# YTM32B1ME0 register map
Vendor: YTMicro; File version: 1.6
YTM32B1ME0 YTMicro Microcontroller
CPU: CM33 r0p4, little endian, MPU, FPU, 2 interrupt priority bits
Registers are 32-bit, read-write, reset 0x0 unless marked. A register's access mark holds for its fields unless they carry their own. Offsets are from the block's base; lines under a group give offsets from that group; [hi:lo] are bit positions; {n}, {i} and the like mark numbered series; 'fields as' and 'values as' point back to an identical list; <NAME> marks a mode.

## Memory map
0x40008000 DMA0 size 0x1200
0x40010000 EFM size 0x400 — Embedded FLASH Module
0x40011000 GPIOA size 0xFF
0x40011100 GPIOB size 0xFF
0x40011200 GPIOC size 0xFF
0x40011300 GPIOD size 0xFF
0x40011400 GPIOE size 0xFF
0x40012000 PCTRLA size 0x80 — PORT Control
0x40013000 PCTRLB size 0x80 — PORT Control
0x40014000 PCTRLC size 0x80 — PORT Control
0x40015000 PCTRLD size 0x80 — PORT Control
0x40016000 PCTRLE size 0x80 — PORT Control
0x4001B000 LINFlexD0 size 0xA0
0x4001C000 LINFlexD1 size 0xA0
0x4001D000 LINFlexD2 size 0xA0
0x4001E000 LINFlexD3 size 0xA0
0x4001F000 LINFlexD4 size 0xA0
0x40020000 LINFlexD5 size 0xA0
0x40023000 I2C0 size 0x120
0x40024000 I2C1 size 0x120
0x40025000 I2C2 size 0x120
0x4002A000 SPI0 size 0x28
0x4002B000 SPI1 size 0x28
0x4002C000 SPI2 size 0x28
0x4002D000 SPI3 size 0x28
0x4002E000 SPI4 size 0x28
0x4002F000 SPI5 size 0x28
0x40030000 CAN0 size 0xC08 — FlexCAN module
0x40034000 CAN1 size 0xC08 — FlexCAN module
0x40038000 CAN2 size 0xC08 — FlexCAN module
0x4003C000 CAN3 size 0xC08 — FlexCAN module
0x4003D000 CAN4 size 0xC08 — FlexCAN module
0x4003E000 CAN5 size 0xC08 — FlexCAN module
0x40040000 ADC0 size 0x54
0x40041000 ADC1 size 0x54
0x40043000 ACMP0 size 0x24 — Analog comparator module
0x40046000 PTU0 size 0x198 — Programmable Trigger Unit
0x40047000 PTU1 size 0x198 — Programmable Trigger Unit
0x40048000 TMU size 0x80 — Trigger Multiplexer Module
0x40049000 eTMR0 size 0x268 — Enhanced timer
0x4004A000 eTMR1 size 0x268 — Enhanced timer
0x4004B000 eTMR2 size 0x268 — Enhanced timer
0x4004C000 eTMR3 size 0x268 — Enhanced timer
0x4004D000 eTMR4 size 0x268 — Enhanced timer
0x4004E000 eTMR5 size 0x268 — Enhanced timer
0x40054000 TMR0 size 0x4C
0x4005A000 pTMR0 size 0x140 — Periodic timer
0x4005D000 lpTMR0 size 0x18 — Low Power Timer
0x40060000 RTC size 0x20
0x40061000 REGFILE size 0x20
0x40062000 WKU size 0x2C — Wake-up Unit
0x40065000 CRC0 size 0x10 — Cyclic Redundancy Check
0x40066000 TRNG size 0x60
0x40067000 HCU size 0xB8 — Hardware Cryptography Unit
0x4006A000 WDG0 size 0x1C — Watchdog module
0x4006B000 EWDG0 size 0x14 — External Watchdog
0x40071000 INTM size 0x12C — Interrupt Monitor
0x40072000 EMU0 size 0x12C — ECC Management Unit
0x4007B000 CIM size 0x58 — Chip Integration Module
0x4007C000 SCU size 0x6C — System Clock Unit of Microcontroller
0x4007D000 IPC size 0x1FC — IP Control
0x4007E000 PCU size 0x20 — Power control unit
0x4007F000 RCU size 0x8 — Reset Contru Unit of Microcontroller

## REGFILE
Base 0x40061000; register names take the prefix REGFILE_
{0x0+4i} DR{i} (i=0..7)
  [31:0] DATA — The data value stored at register file block. The register is only reseted by POR.

## GPIOA
Base 0x40011000; register names take the prefix GPIOA_
0x00 PDOR
  [31:0] PDO — When configured for general-purpose output, it shows the logic level on the corresponding pin.
0x04 PSOR wo
  [31:0] PSO — Writing to this register will update the contents of the corresponding bit in PDOR. 0b - No change. 1b - Corresponding bit in PDOR is set to logic 1.
0x08 PCOR wo
  [31:0] PCO — Writing to this register will update the contents of the corresponding bit in PDOR. 0b - No change. 1b - Corresponding bit in PDOR is set to logic 0.
0x0C PTOR wo
  [31:0] PTO — Writing to this register will update the contents of the corresponding bit in PDOR. 0b - No change. 1b - Corresponding bit in PDOR is set to the inverse of its existing logic state.
0x10 PDIR ro
  [31:0] PDI — When configured for digital function, it shows the logic level on the corresponding pin. ewline When configured for analog function, it always reads 0.
0x14 POER
  [31:0] POE — Configure the corresponding pin for output. 0b - Port output disable 1b - Port output enable
0x18 PIER reset 0xFFFFFFFF
  [31:0] PIE — Configure the corresponding pin for input. 0b - Port input disable 1b - Port input enable
0x1C PIFR
  [31:0] PIF — Indicate the detection for the defined event in PCR[IRQC] of the corresponding pin. 0b - No event detected. 1b - The event defined in PCR[IRQC] is detected.
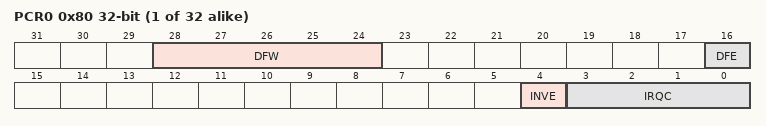
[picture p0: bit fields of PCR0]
{0x80+4i} PCR{i} (i=0..31)
  [28:24] DFW — The digital filter configuration is valid in all digital pin muxing modes. Glitches that are longer than this register setting will pass through the digital filter, and glitches that are equal to or less than this register setting are filtered. Changing the filter length must be done only after all filters are disabled.
  [16] DFE
  [4] INVE — Invert the input logic level when configured for digital function.
  [3:0] IRQC
    0=Disabled; 1=DMA request on rising edge; 2=DMA request on falling edge; 3=DMA request on either edge; 8=Interrupt when logic 0; 9=Interrupt on rising-edge; 10=Interrupt on falling-edge; 11=Interrupt on either edge; 12=Interrupt when logic 1

## GPIOB
Base 0x40011100; register names take the prefix GPIOB_
Registers as GPIOA.

## GPIOC
Base 0x40011200; register names take the prefix GPIOC_
Registers as GPIOA.

## GPIOD
Base 0x40011300; register names take the prefix GPIOD_
Registers as GPIOA.

## GPIOE
Base 0x40011400; register names take the prefix GPIOE_
Registers as GPIOA.

## Licence text in the file
YTMicro Microcontroller all rights reserved.
